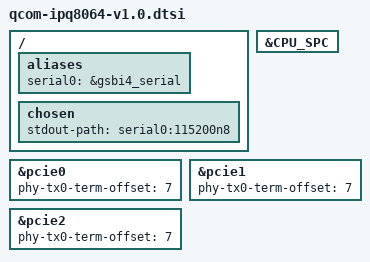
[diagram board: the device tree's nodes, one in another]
#include "qcom-ipq8064.dtsi"

/ {
	aliases {
		serial0 = &gsbi4_serial;
	};

	chosen {
		stdout-path = "serial0:115200n8";
	};
};

&CPU_SPC {
	status = "okay";
};

&pcie0 {
	phy-tx0-term-offset = <7>;
};

&pcie1 {
	phy-tx0-term-offset = <7>;
};

&pcie2 {
	phy-tx0-term-offset = <7>;
};
